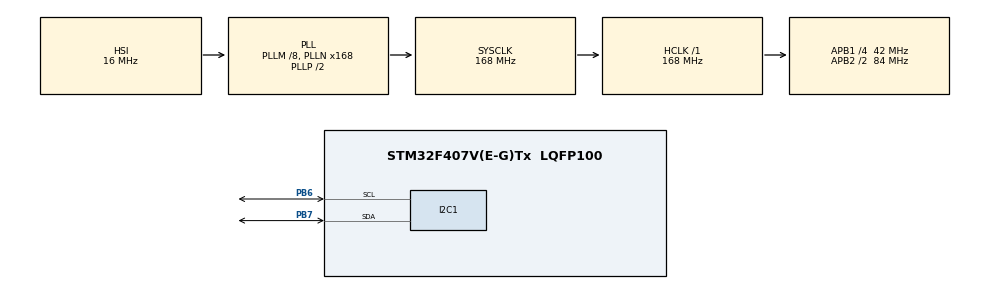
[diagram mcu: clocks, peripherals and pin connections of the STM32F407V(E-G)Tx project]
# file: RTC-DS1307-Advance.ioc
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Mcu.Family=STM32F4
Mcu.Name=STM32F407V(E-G)Tx
Mcu.Package=LQFP100
NVIC.PriorityGroup=NVIC_PRIORITYGROUP_4
PB6.Mode=I2C
PB6.Signal=I2C1_SCL
PB7.Mode=I2C
PB7.Signal=I2C1_SDA
ProjectManager.HeapSize=0x200
ProjectManager.StackSize=0x400
ProjectManager.TargetToolchain=MDK-ARM V5.27
RCC.48MHZClocksFreq_Value=84000000
RCC.AHBFreq_Value=168000000
RCC.APB1CLKDivider=RCC_HCLK_DIV4
RCC.APB1Freq_Value=42000000
RCC.APB1TimFreq_Value=84000000
RCC.APB2CLKDivider=RCC_HCLK_DIV2
RCC.APB2Freq_Value=84000000
RCC.APB2TimFreq_Value=168000000
RCC.CortexFreq_Value=168000000
RCC.HCLKFreq_Value=168000000
RCC.HSE_VALUE=25000000
RCC.HSI_VALUE=16000000
RCC.LSE_VALUE=32768
RCC.PLLM=8
RCC.PLLN=168
RCC.SYSCLKFreq_VALUE=168000000
RCC.SYSCLKSource=RCC_SYSCLKSOURCE_PLLCLK
RCC.VCOOutputFreq_Value=336000000
board=custom

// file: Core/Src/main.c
/* USER CODE BEGIN Header */
/**
  ******************************************************************************
  * @file           : main.c
  * @brief          : Main program body
  ******************************************************************************
  * @attention
  *
  * <h2><center>&copy; Copyright (c) 2023 STMicroelectronics.
  * All rights reserved.</center></h2>
  *
  * This software component is licensed by ST under BSD 3-Clause license,
  * the "License"; You may not use this file except in compliance with the
  * License. You may obtain a copy of the License at:
  *                        opensource.org/licenses/BSD-3-Clause
  *
  ******************************************************************************
  */
/* USER CODE END Header */
#include "main.h"
#include "i2c.h"
#include "gpio.h"

/* USER CODE BEGIN Includes */
#include "ALCD.h"
/* USER CODE END Includes */

/* USER CODE BEGIN PTD */
typedef struct {
  uint8_t       Seconds;
  uint8_t       Minutes;
  uint8_t       Hours;
  uint8_t       WeekDay;
  uint8_t       Day;
  uint8_t       Month;
  uint8_t       Year;
  uint8_t       Control;
  uint8_t       RAM[56];
} DS1307_Map;

typedef struct {
  uint8_t       Seconds;
  uint8_t       Minutes;
  uint8_t       Hours;
} DS1307_Time;

typedef struct {
  uint8_t       WeekDay;
  uint8_t       Day;
  uint8_t       Month;
  uint8_t       Year;
} DS1307_Date;

typedef union {
  // Structure
  struct {
    DS1307_Time   Time;
    DS1307_Time   Date;
  };
  // Separated
  struct {
    uint8_t       Seconds;
    uint8_t       Minutes;
    uint8_t       Hours;
    uint8_t       WeekDay;
    uint8_t       Day;
    uint8_t       Month;
    uint8_t       Year;
  };
} DS1307_DateTime;

/* USER CODE END PTD */

/* USER CODE BEGIN PD */
#define DS1307_DEV_ADDR           0xD0

//#define DS1307_ADDR_TIME          0
#define DS1307_ADDR_TIME          ((uint32_t) &((DS1307_Map*) 0)->Seconds)
//#define DS1307_ADDR_DATE          3
#define DS1307_ADDR_DATE          ((uint32_t) &((DS1307_Map*) 0)->WeekDay)
//#define DS1307_ADDR_DATE          0
#define DS1307_ADDR_DATE_TIME     ((uint32_t) &((DS1307_Map*) 0)->Seconds)

/* USER CODE END PD */

void SystemClock_Config(void);
/* USER CODE BEGIN PFP */

uint8_t RTC_isRunning(void);

HAL_StatusTypeDef RTC_setTime(DS1307_Time* v);
HAL_StatusTypeDef RTC_setDate(DS1307_Date* v);
HAL_StatusTypeDef RTC_setDateTime(DS1307_DateTime* v);

HAL_StatusTypeDef RTC_getTime(DS1307_Time* v);
HAL_StatusTypeDef RTC_getDate(DS1307_Date* v);
HAL_StatusTypeDef RTC_getDateTime(DS1307_DateTime* v);

void bcdToBin(uint8_t* dst, uint8_t* src, uint16_t len);
void binToBcd(uint8_t* dst, uint8_t* src, uint16_t len);

/* USER CODE END PFP */

int main(void)
{
  /* USER CODE BEGIN 1 */
  DS1307_DateTime datetime;
  /* USER CODE END 1 */

  /* MCU Configuration--------------------------------------------------------*/

  /* Reset of all peripherals, Initializes the Flash interface and the Systick. */
  HAL_Init();

  /* Configure the system clock */
  SystemClock_Config();

  /* Initialize all configured peripherals */
  MX_GPIO_Init();
  MX_I2C1_Init();
  /* USER CODE BEGIN 2 */
  ALCD_init(16, 2);
  ALCD_clear();

  if (!RTC_isRunning()) {
    datetime.Year = 23;
    datetime.Month = 12;
    datetime.Day = 11;
    datetime.WeekDay = 3;
    datetime.Hours = 14;
    datetime.Minutes = 22;
    datetime.Seconds = 25;
    RTC_setDateTime(&datetime);
  }

  /* USER CODE END 2 */

  /* Infinite loop */
  /* USER CODE BEGIN WHILE */
  while (1)
  {
    RTC_getTime(&datetime.Time);
    ALCD_printfXY(4, 0, "%02u:%02u:%02u", datetime.Hours, datetime.Minutes, datetime.Seconds);
    HAL_Delay(1000);
    /* USER CODE END WHILE */

  }
}

void SystemClock_Config(void)
{
  RCC_OscInitTypeDef RCC_OscInitStruct = {0};
  RCC_ClkInitTypeDef RCC_ClkInitStruct = {0};

  /** Configure the main internal regulator output voltage
  */
  __HAL_RCC_PWR_CLK_ENABLE();
  __HAL_PWR_VOLTAGESCALING_CONFIG(PWR_REGULATOR_VOLTAGE_SCALE1);
  /** Initializes the RCC Oscillators according to the specified parameters
  * in the RCC_OscInitTypeDef structure.
  */
  RCC_OscInitStruct.OscillatorType = RCC_OSCILLATORTYPE_HSI;
  RCC_OscInitStruct.HSIState = RCC_HSI_ON;
  RCC_OscInitStruct.HSICalibrationValue = RCC_HSICALIBRATION_DEFAULT;
  RCC_OscInitStruct.PLL.PLLState = RCC_PLL_ON;
  RCC_OscInitStruct.PLL.PLLSource = RCC_PLLSOURCE_HSI;
  RCC_OscInitStruct.PLL.PLLM = 8;
  RCC_OscInitStruct.PLL.PLLN = 168;
  RCC_OscInitStruct.PLL.PLLP = RCC_PLLP_DIV2;
  RCC_OscInitStruct.PLL.PLLQ = 4;
  if (HAL_RCC_OscConfig(&RCC_OscInitStruct) != HAL_OK)
  {
    Error_Handler();
  }
  /** Initializes the CPU, AHB and APB buses clocks
  */
  RCC_ClkInitStruct.ClockType = RCC_CLOCKTYPE_HCLK|RCC_CLOCKTYPE_SYSCLK
                              |RCC_CLOCKTYPE_PCLK1|RCC_CLOCKTYPE_PCLK2;
  RCC_ClkInitStruct.SYSCLKSource = RCC_SYSCLKSOURCE_PLLCLK;
  RCC_ClkInitStruct.AHBCLKDivider = RCC_SYSCLK_DIV1;
  RCC_ClkInitStruct.APB1CLKDivider = RCC_HCLK_DIV4;
  RCC_ClkInitStruct.APB2CLKDivider = RCC_HCLK_DIV2;

  if (HAL_RCC_ClockConfig(&RCC_ClkInitStruct, FLASH_LATENCY_5) != HAL_OK)
  {
    Error_Handler();
  }
}

/* USER CODE BEGIN 4 */
uint8_t RTC_isRunning(void) {
  uint8_t buf[1];
  if (HAL_I2C_Mem_Read(&hi2c1, DS1307_DEV_ADDR, 0, I2C_MEMADD_SIZE_8BIT, buf, sizeof(buf), 1000) == HAL_OK) {
    return (buf[0] & 0x80) == 0;
  }
  else {
    return 0;
  }
}

HAL_StatusTypeDef RTC_setTime(DS1307_Time* v) {
  DS1307_Time buf;
  binToBcd((uint8_t*) &buf, (uint8_t*) v, sizeof(buf));
  return HAL_I2C_Mem_Write(&hi2c1, DS1307_DEV_ADDR, DS1307_ADDR_TIME, I2C_MEMADD_SIZE_8BIT, (uint8_t*) &buf, sizeof(buf), 1000);
}
HAL_StatusTypeDef RTC_setDate(DS1307_Date* v) {
  DS1307_Date buf;
  binToBcd((uint8_t*) &buf, (uint8_t*) v, sizeof(buf));
  return HAL_I2C_Mem_Write(&hi2c1, DS1307_DEV_ADDR, DS1307_ADDR_DATE, I2C_MEMADD_SIZE_8BIT, (uint8_t*) &buf, sizeof(buf), 1000);
}
HAL_StatusTypeDef RTC_setDateTime(DS1307_DateTime* v) {
  DS1307_DateTime buf;
  binToBcd((uint8_t*) &buf, (uint8_t*) v, sizeof(buf));
  return HAL_I2C_Mem_Write(&hi2c1, DS1307_DEV_ADDR, DS1307_ADDR_DATE_TIME, I2C_MEMADD_SIZE_8BIT, (uint8_t*) &buf, sizeof(buf), 1000);
}

HAL_StatusTypeDef RTC_getTime(DS1307_Time* v) {
  HAL_StatusTypeDef result;
  result = HAL_I2C_Mem_Read(&hi2c1, DS1307_DEV_ADDR, DS1307_ADDR_TIME, I2C_MEMADD_SIZE_8BIT, (uint8_t*) v, sizeof(*v), 1000);
  if (result == HAL_OK) {
    bcdToBin((uint8_t*) v, (uint8_t*) v, sizeof(*v));
  }
  return result;
}
HAL_StatusTypeDef RTC_getDate(DS1307_Date* v) {
  HAL_StatusTypeDef result;
  result = HAL_I2C_Mem_Read(&hi2c1, DS1307_DEV_ADDR, DS1307_ADDR_DATE, I2C_MEMADD_SIZE_8BIT, (uint8_t*) v, sizeof(*v), 1000);
  if (result == HAL_OK) {
    bcdToBin((uint8_t*) v, (uint8_t*) v, sizeof(*v));
  }
  return result;
}
HAL_StatusTypeDef RTC_getDateTime(DS1307_DateTime* v) {
  HAL_StatusTypeDef result;
  result = HAL_I2C_Mem_Read(&hi2c1, DS1307_DEV_ADDR, DS1307_ADDR_DATE_TIME, I2C_MEMADD_SIZE_8BIT, (uint8_t*) v, sizeof(*v), 1000);
  if (result == HAL_OK) {
    bcdToBin((uint8_t*) v, (uint8_t*) v, sizeof(*v));
  }
  return result;
}

void bcdToBin(uint8_t* dst, uint8_t* src, uint16_t len) {
  while (len-- > 0) {
    *dst++ = (*src & 0x0F) + (((*src >> 4) & 0x0F) * 10);
    src++;
  }
}
void binToBcd(uint8_t* dst, uint8_t* src, uint16_t len) {
  while (len-- > 0) {
    *dst++ = (*src % 10) | ((*src / 10) << 4);
    src++;
  }
}
/* USER CODE END 4 */

void Error_Handler(void)
{
  __disable_irq();
  while (1)
  {
  }
}

/************************ (C) COPYRIGHT STMicroelectronics *****END OF FILE****/
